VERSION ""

NS_ :

BS_:

BU_: Vector__XXX

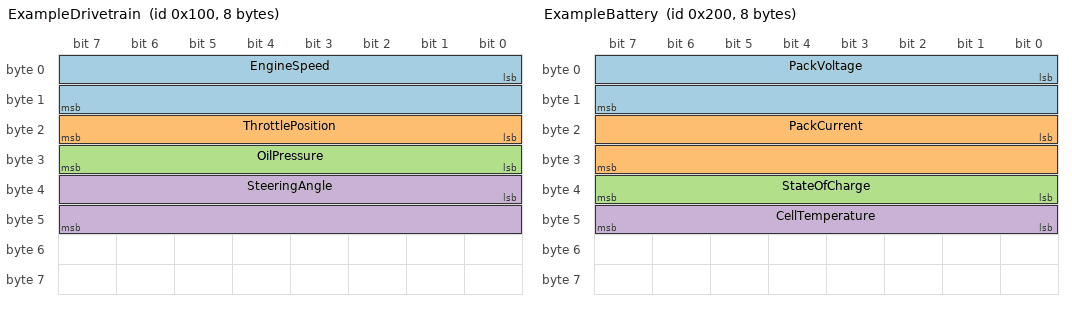
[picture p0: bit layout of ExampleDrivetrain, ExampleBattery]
BO_ 256 ExampleDrivetrain: 8 Vector__XXX
 SG_ EngineSpeed : 0|16@1+ (0.125,0) [0|8000] "rpm" Vector__XXX
 SG_ ThrottlePosition : 16|8@1+ (0.5,0) [0|100] "%" Vector__XXX
 SG_ OilPressure : 24|8@1+ (1,0) [0|255] "kPa" Vector__XXX
 SG_ SteeringAngle : 32|16@1- (0.1,0) [-180|180] "deg" Vector__XXX

BO_ 512 ExampleBattery: 8 Vector__XXX
 SG_ PackVoltage : 0|16@1+ (0.1,0) [0|600] "V" Vector__XXX
 SG_ PackCurrent : 16|16@1- (0.1,0) [-300|300] "A" Vector__XXX
 SG_ StateOfCharge : 32|8@1+ (0.5,0) [0|100] "%" Vector__XXX
 SG_ CellTemperature : 40|8@1+ (1,-40) [-40|215] "C" Vector__XXX

CM_ BO_ 256 "Sample drivetrain message for development and testing";
CM_ BO_ 512 "Sample battery telemetry message for development and testing";
CM_ SG_ 256 EngineSpeed "Engine crankshaft speed";
CM_ SG_ 256 ThrottlePosition "Driver throttle pedal position";
CM_ SG_ 256 OilPressure "Lubrication system pressure";
CM_ SG_ 256 SteeringAngle "Front wheel steering angle";
CM_ SG_ 512 PackVoltage "High voltage pack voltage";
CM_ SG_ 512 PackCurrent "High voltage pack current";
CM_ SG_ 512 StateOfCharge "Estimated battery state of charge";
CM_ SG_ 512 CellTemperature "Representative cell temperature";
